# SF32LB56x register map
File version: 1.0
CPU: CM33 r0p1, little endian, MPU, FPU, 3 interrupt priority bits
Registers are 32-bit, read-write, reset 0x0 unless marked. A register's access mark holds for its fields unless they carry their own. Offsets are from the block's base; [hi:lo] are bit positions; {n}, {i} and the like mark numbered series.

## LPSYS_CFG
Base 0x5000F000
0x00 SWCR — SW Control Register
  [0] SWSEL — 0: SWD connected to HCPU 1: SWD connected to LCPU
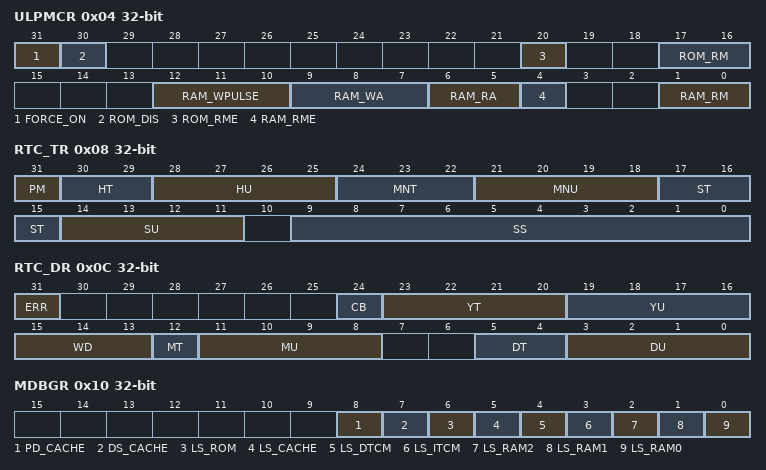
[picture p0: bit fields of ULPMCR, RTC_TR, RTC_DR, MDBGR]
0x04 ULPMCR — ULP Memory Control register
  [31] FORCE_ON — reserved for debug
  [30] ROM_DIS — reserved for debug
  [20] ROM_RME — reserved for debug
  [17:16] ROM_RM — reserved for debug
  [12:10] RAM_WPULSE — reserved for debug
  [9:7] RAM_WA — reserved for debug
  [6:5] RAM_RA — reserved for debug
  [4] RAM_RME — reserved for debug
  [1:0] RAM_RM — reserved for debug
0x08 RTC_TR — Mirrored RTC Time Register
  [31] PM — AM/PM notation 0: AM 1: PM
  [30:29] HT — Hour tens in BCD format
  [28:25] HU — Hour units in BCD format
  [24:22] MNT — Minute tens in BCD format
  [21:18] MNU — Minute units in BCD format
  [17:15] ST — Second tens in BCD format
  [14:11] SU — Second units in BCD format
  [9:0] SS — Sub-second counter
0x0C RTC_DR — Mirrored RTC Date Register
  [31] ERR — reserved for debug
  [24] CB — Century flag
  [23:20] YT — Year tens in BCD format
  [19:16] YU — Year units in BCD format
  [15:13] WD — Week day units 000: forbidden 001: Monday ... 111: Sunday
  [12] MT — Month tens in BCD format
  [11:8] MU — Month units in BCD format
  [5:4] DT — Date tens in BCD format
  [3:0] DU — Date units in BCD format
0x10 MDBGR — Memory Debug Register
  [8] PD_CACHE — reserved for debug
  [7] DS_CACHE — reserved for debug
  [6] LS_ROM — reserved for debug
  [5] LS_CACHE — reserved for debug
  [4] LS_DTCM — reserved for debug
  [3] LS_ITCM — reserved for debug
  [2] LS_RAM2 — reserved for debug
  [1] LS_RAM1 — reserved for debug
  [0] LS_RAM0 — reserved for debug
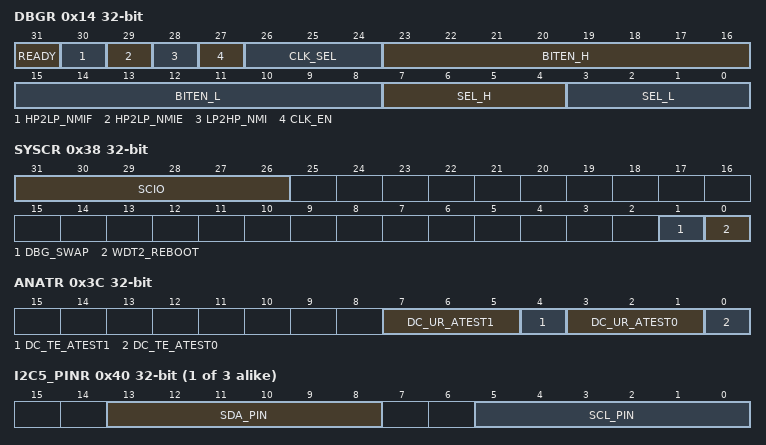
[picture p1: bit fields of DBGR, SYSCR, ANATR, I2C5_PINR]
0x14 DBGR — Debug Register
  [31] READY — reserved for debug
  [30] HP2LP_NMIF — HP2LP NMI interrupt flag
  [29] HP2LP_NMIE — HP2LP NMI interrupt enable
  [28] LP2HP_NMI — set 1 to send NMI interrupt to HCPU
  [27] CLK_EN — reserved for debug
  [26:24] CLK_SEL — reserved for debug
  [23:16] BITEN_H — reserved for debug
  [15:8] BITEN_L — reserved for debug
  [7:4] SEL_H — reserved for debug
  [3:0] SEL_L — reserved for debug
0x38 SYSCR — System Configure Register
  [31:26] SCIO — reserved for debug
  [1] DBG_SWAP — reserved for debug
  [0] WDT2_REBOOT — If set to 1, WDT2 reset will reboot the whole chip
0x3C ANATR — Analog Test Register
  [7:5] DC_UR_ATEST1 — reserved for debug
  [4] DC_TE_ATEST1 — reserved for debug
  [3:1] DC_UR_ATEST0 — reserved for debug
  [0] DC_TE_ATEST0 — reserved for debug
{0x2C+4i} I2C{i}_PINR (i=5..7) — I2C{i} Pin Register
  [13:8] SDA_PIN — Connect function pin to selected IO(PB). 0 to 31 for PB00 to PB31. Other values for floating.
  [5:0] SCL_PIN — Connect function pin to selected IO(PB). 0 to 31 for PB00 to PB31. Other values for floating.
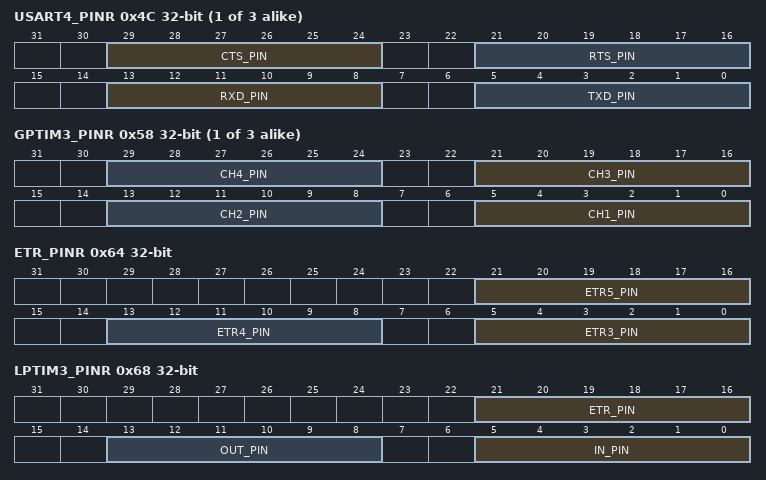
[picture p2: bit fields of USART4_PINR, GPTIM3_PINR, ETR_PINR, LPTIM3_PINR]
{0x3C+4i} USART{i}_PINR (i=4..6) — USART{i} Pin Register
  [29:24] CTS_PIN — Connect function pin to selected IO(PB). 0 to 31 for PB00 to PB31. Other values for floating.
  [21:16] RTS_PIN — Connect function pin to selected IO(PB). 0 to 31 for PB00 to PB31. Other values for floating.
  [13:8] RXD_PIN — Connect function pin to selected IO(PB). 0 to 31 for PB00 to PB31. Other values for floating.
  [5:0] TXD_PIN — Connect function pin to selected IO(PB). 0 to 31 for PB00 to PB31. Other values for floating.
{0x4C+4i} GPTIM{i}_PINR (i=3..5) — GPTIM{i} Pin Register
  [8n-3:8n-8] CH{n}_PIN (n=1..4) — Connect function pin to selected IO(PB). 0 to 31 for PB00 to PB31. Other values for floating.
0x64 ETR_PINR — ETR Pin Register
  [21:16] ETR5_PIN — Connect GPTIM5_ETR to selected IO(PB). 0 to 31 for PB00 to PB31. Other values for floating.
  [13:8] ETR4_PIN — Connect GPTIM4_ETR to selected IO(PB). 0 to 31 for PB00 to PB31. Other values for floating.
  [5:0] ETR3_PIN — Connect GPTIM3_ETR to selected IO(PB). 0 to 31 for PB00 to PB31. Other values for floating.
0x68 LPTIM3_PINR — LPTIM3 Pin Register
  [21:16] ETR_PIN — Connect function pin to selected IO(PB). 0 to 31 for PB00 to PB31. Other values for floating.
  [13:8] OUT_PIN — Connect function pin to selected IO(PB). 0 to 31 for PB00 to PB31. Other values for floating.
  [5:0] IN_PIN — Connect function pin to selected IO(PB). 0 to 31 for PB00 to PB31. Other values for floating.
